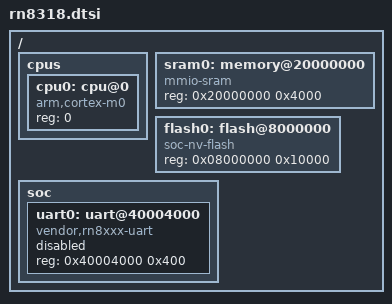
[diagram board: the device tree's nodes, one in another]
#include <arm/armv6-m.dtsi>

/ {
    cpus {
        #address-cells = <1>;
        #size-cells = <0>;

        cpu0: cpu@0 {
            device_type = "cpu";
            compatible = "arm,cortex-m0";
            reg = <0>;
        };
    };

    sram0: memory@20000000 {
        compatible = "mmio-sram";
        reg = <0x20000000 0x4000>;
    };

    flash0: flash@8000000 {
        compatible = "soc-nv-flash";
        reg = <0x08000000 0x10000>;
    };

    soc {
        uart0: uart@40004000 {
            compatible = "vendor,rn8xxx-uart";
            reg = <0x40004000 0x400>;
            status = "disabled";
        };
    };
};
